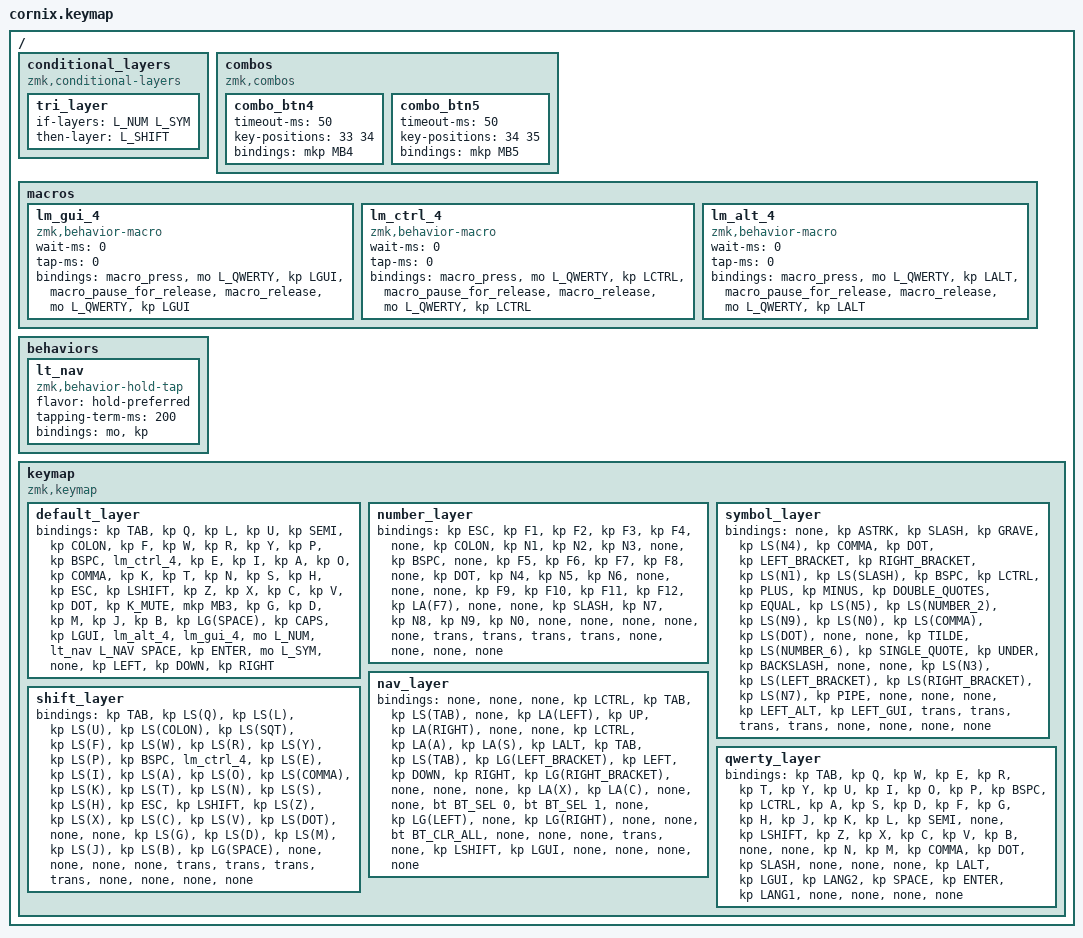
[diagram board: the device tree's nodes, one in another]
/*
 * Copyright (c) 2020 The ZMK Contributors
 * SPDX-License-Identifier: MIT
 */

#include <dt-bindings/zmk/mouse.h>
#include <behaviors/mouse_keys.dtsi>
#include <behaviors.dtsi>
#include <dt-bindings/zmk/bt.h>
#include <dt-bindings/zmk/keys.h>
#include <dt-bindings/zmk/pointing.h>

#define L_BASE 0
#define L_NUM 1
#define L_SYM 2
#define L_NAV 3
#define L_QWERTY 4
#define L_SHIFT 5

/ {
    // 【新設】QMKのオーバーラップ（同時押しレイヤー）を完璧に再現する公式機能

    conditional_layers {
        compatible = "zmk,conditional-layers";

        tri_layer {
            if-layers = <L_NUM L_SYM>;
            then-layer = <L_SHIFT>;
        };
    };

    combos {
        compatible = "zmk,combos";

        // Vial時代のコンボの移植 (50キー完全対応版)

        combo_btn4 {
            timeout-ms = <50>;
            key-positions = <33 34>;
            bindings = <&mkp MB4>;
        }; // D + M
        combo_btn5 {
            timeout-ms = <50>;
            key-positions = <34 35>;
            bindings = <&mkp MB5>;
        }; // M + J
    };

    macros {
        lm_gui_4: lm_gui_4 {
            compatible = "zmk,behavior-macro";
            #binding-cells = <0>;
            wait-ms = <0>;
            tap-ms = <0>;
            bindings =
                <&macro_press>,
                <&mo L_QWERTY &kp LGUI>,
                <&macro_pause_for_release>,
                <&macro_release>,
                <&mo L_QWERTY &kp LGUI>;
        };

        lm_ctrl_4: lm_ctrl_4 {
            compatible = "zmk,behavior-macro";
            #binding-cells = <0>;
            wait-ms = <0>;
            tap-ms = <0>;
            bindings =
                <&macro_press>,
                <&mo L_QWERTY &kp LCTRL>,
                <&macro_pause_for_release>,
                <&macro_release>,
                <&mo L_QWERTY &kp LCTRL>;
        };

        lm_alt_4: lm_alt_4 {
            compatible = "zmk,behavior-macro";
            #binding-cells = <0>;
            wait-ms = <0>;
            tap-ms = <0>;
            bindings =
                <&macro_press>,
                <&mo L_QWERTY &kp LALT>,
                <&macro_pause_for_release>,
                <&macro_release>,
                <&mo L_QWERTY &kp LALT>;
        };
    };

    behaviors {
        // NAV用：単押しでSPACE、長押しでL_NAVレイヤー

        lt_nav: lt_nav {
            compatible = "zmk,behavior-hold-tap";
            #binding-cells = <2>;
            flavor = "hold-preferred";
            tapping-term-ms = <200>;
            bindings = <&mo>, <&kp>;
        };
    };

    keymap {
        compatible = "zmk,keymap";

        // Layer 0: Default

        default_layer {
            bindings = <
&kp TAB  &kp Q  &kp L  &kp U  &kp SEMI  &kp COLON  &kp F  &kp W  &kp R  &kp Y  &kp P  &kp BSPC  &lm_ctrl_4  &kp E  &kp I  &kp A  &kp O  &kp COMMA  &kp K  &kp T  &kp N  &kp S  &kp H  &kp ESC  &kp LSHIFT  &kp Z  &kp X  &kp C  &kp V  &kp DOT  &kp K_MUTE  &mkp MB3  &kp G  &kp D  &kp M  &kp J  &kp B  &kp LG(SPACE)  &kp CAPS  &kp LGUI  &lm_alt_4  &lm_gui_4  &mo L_NUM  &lt_nav L_NAV SPACE  &kp ENTER  &mo L_SYM  &none  &kp LEFT  &kp DOWN  &kp RIGHT
            >;
        };

        // Layer 1: NUM 
        // （親指部分はすべて &trans にし、ZMKに素直にレイヤー判定を任せます）

        number_layer {
            bindings = <
&kp ESC  &kp F1  &kp F2  &kp F3  &kp F4  &none  &kp COLON  &kp N1  &kp N2  &kp N3  &none  &kp BSPC  &none  &kp F5  &kp F6  &kp F7  &kp F8  &none  &kp DOT  &kp N4  &kp N5  &kp N6  &none  &none  &none  &kp F9  &kp F10  &kp F11  &kp F12  &kp LA(F7)  &none  &none  &kp SLASH  &kp N7  &kp N8  &kp N9  &kp N0  &none  &none  &none  &none  &none  &trans  &trans  &trans  &trans  &none  &none  &none  &none
            >;
        };

        // Layer 2: SYM
        // （こちらも親指部分はすべて &trans にします）

        symbol_layer {
            bindings = <
&none  &kp ASTRK  &kp SLASH  &kp GRAVE  &kp LS(N4)  &kp COMMA  &kp DOT  &kp LEFT_BRACKET  &kp RIGHT_BRACKET  &kp LS(N1)  &kp LS(SLASH)  &kp BSPC  &kp LCTRL  &kp PLUS  &kp MINUS  &kp DOUBLE_QUOTES  &kp EQUAL  &kp LS(N5)  &kp LS(NUMBER_2)  &kp LS(N9)  &kp LS(N0)  &kp LS(COMMA)  &kp LS(DOT)  &none  &none  &kp TILDE  &kp LS(NUMBER_6)  &kp SINGLE_QUOTE  &kp UNDER  &kp BACKSLASH  &none  &none  &kp LS(N3)  &kp LS(LEFT_BRACKET)  &kp LS(RIGHT_BRACKET)  &kp LS(N7)  &kp PIPE  &none  &none  &none  &kp LEFT_ALT  &kp LEFT_GUI  &trans  &trans  &trans  &trans  &none  &none  &none  &none
            >;
        };

        // Layer 3: NAV (シンプルに修飾キーとTABを並べる構成)

        nav_layer {
            bindings = <
&none  &none  &none  &kp LCTRL  &kp TAB  &kp LS(TAB)  &none  &kp LA(LEFT)  &kp UP  &kp LA(RIGHT)  &none  &none  &kp LCTRL  &kp LA(A)  &kp LA(S)  &kp LALT  &kp TAB  &kp LS(TAB)  &kp LG(LEFT_BRACKET)  &kp LEFT  &kp DOWN  &kp RIGHT  &kp LG(RIGHT_BRACKET)  &none  &none  &none  &kp LA(X)  &kp LA(C)  &none  &none  &bt BT_SEL 0  &bt BT_SEL 1  &none  &kp LG(LEFT)  &none  &kp LG(RIGHT)  &none  &none  &bt BT_CLR_ALL  &none  &none  &none  &trans  &none  &kp LSHIFT  &kp LGUI  &none  &none  &none  &none
            >;
        };

        // Layer 4: QWERTY

        qwerty_layer {
            bindings = <
&kp TAB  &kp Q  &kp W  &kp E  &kp R  &kp T  &kp Y  &kp U  &kp I  &kp O  &kp P  &kp BSPC  &kp LCTRL  &kp A  &kp S  &kp D  &kp F  &kp G  &kp H  &kp J  &kp K  &kp L  &kp SEMI  &none  &kp LSHIFT  &kp Z  &kp X  &kp C  &kp V  &kp B  &none  &none  &kp N  &kp M  &kp COMMA  &kp DOT  &kp SLASH  &none  &none  &none  &kp LALT  &kp LGUI  &kp LANG2  &kp SPACE  &kp ENTER  &kp LANG1  &none  &none  &none  &none
            >;
        };

        // Layer 5: 大文字入力専用レイヤー (親指はすべて &trans)

        shift_layer {
            bindings = <
&kp TAB  &kp LS(Q)  &kp LS(L)  &kp LS(U)  &kp LS(COLON)  &kp LS(SQT)  &kp LS(F)  &kp LS(W)  &kp LS(R)  &kp LS(Y)  &kp LS(P)  &kp BSPC  &lm_ctrl_4  &kp LS(E)  &kp LS(I)  &kp LS(A)  &kp LS(O)  &kp LS(COMMA)  &kp LS(K)  &kp LS(T)  &kp LS(N)  &kp LS(S)  &kp LS(H)  &kp ESC  &kp LSHIFT  &kp LS(Z)  &kp LS(X)  &kp LS(C)  &kp LS(V)  &kp LS(DOT)  &none  &none  &kp LS(G)  &kp LS(D)  &kp LS(M)  &kp LS(J)  &kp LS(B)  &kp LG(SPACE)  &none  &none  &none  &none  &trans  &trans  &trans  &trans  &none  &none  &none  &none
            >;
        };
    };
};
